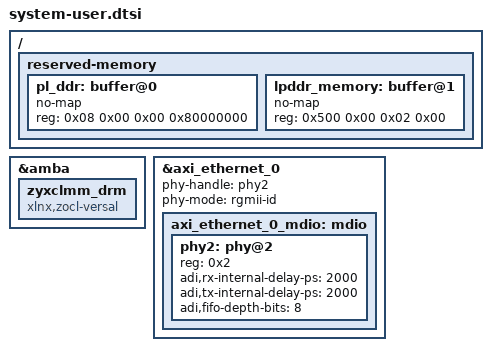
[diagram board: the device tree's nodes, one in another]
/include/ "system-conf.dtsi"
/ {

reserved-memory {
        #address-cells = <2>;
        #size-cells = <2>;
        ranges;
        pl_ddr: buffer@0
        {
        no-map;
        reg = <0x08 0x00 0x00 0x80000000>;
        };

        lpddr_memory: buffer@1
        {
        no-map;
        reg = <0x500 0x00 0x02 0x00>;
        };

};


};

&amba {
        zyxclmm_drm {
                compatible = "xlnx,zocl-versal";
        };
};

&axi_ethernet_0 {
        phy-handle = <&phy2>;
        phy-mode = "rgmii-id";
        axi_ethernet_0_mdio: mdio {
        #address-cells = <1>;
        #size-cells = <0>;
        phy2: phy@2 {
                reg = <0x2>;
                adi,rx-internal-delay-ps = <2000>;
                adi,tx-internal-delay-ps = <2000>;
                adi,fifo-depth-bits = <8>;
                };
        };

};
